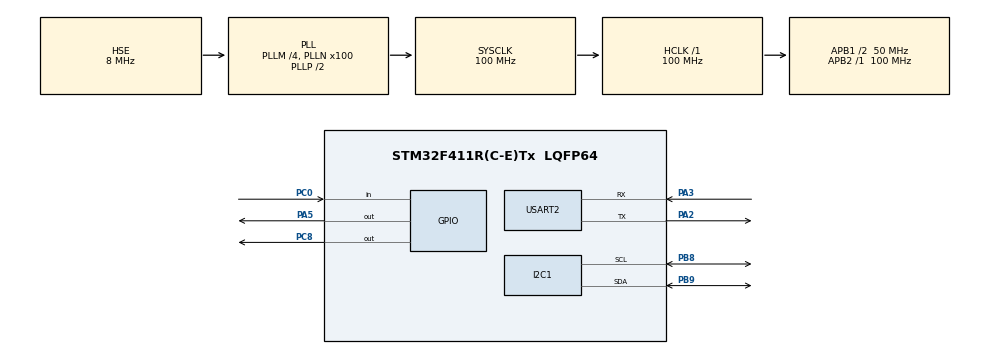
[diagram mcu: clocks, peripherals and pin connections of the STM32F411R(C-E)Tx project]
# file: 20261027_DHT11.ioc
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Mcu.Family=STM32F4
Mcu.Name=STM32F411R(C-E)Tx
Mcu.Package=LQFP64
NVIC.PriorityGroup=NVIC_PRIORITYGROUP_4
PA13.Signal=SYS_JTMS-SWDIO
PA14.Signal=SYS_JTCK-SWCLK
PA2.Mode=Asynchronous
PA2.Signal=USART2_TX
PA3.Mode=Asynchronous
PA3.Signal=USART2_RX
PA5.Signal=GPIO_Output
PB8.Mode=I2C
PB8.Signal=I2C1_SCL
PB9.Mode=I2C
PB9.Signal=I2C1_SDA
PC0.Signal=GPIO_Input
PC8.Signal=GPIO_Output
PH0\ -\ OSC_IN.Mode=HSE-External-Oscillator
PH0\ -\ OSC_IN.Signal=RCC_OSC_IN
PH1\ -\ OSC_OUT.Mode=HSE-External-Oscillator
PH1\ -\ OSC_OUT.Signal=RCC_OSC_OUT
ProjectManager.HeapSize=0x200
ProjectManager.StackSize=0x400
ProjectManager.TargetToolchain=STM32CubeIDE
RCC.48MHZClocksFreq_Value=50000000
RCC.AHBFreq_Value=100000000
RCC.APB1CLKDivider=RCC_HCLK_DIV2
RCC.APB1Freq_Value=50000000
RCC.APB1TimFreq_Value=100000000
RCC.APB2Freq_Value=100000000
RCC.APB2TimFreq_Value=100000000
RCC.CortexFreq_Value=100000000
RCC.HCLKFreq_Value=100000000
RCC.HSE_VALUE=8000000
RCC.HSI_VALUE=16000000
RCC.LSE_VALUE=32768
RCC.PLLM=4
RCC.PLLN=100
RCC.PLLSourceVirtual=RCC_PLLSOURCE_HSE
RCC.SYSCLKFreq_VALUE=100000000
RCC.SYSCLKSource=RCC_SYSCLKSOURCE_PLLCLK
RCC.VCOOutputFreq_Value=200000000
USART2.VirtualMode=VM_ASYNC
board=custom

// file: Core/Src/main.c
/* USER CODE BEGIN Header */
/**
 ******************************************************************************
 * @file           : main.c
 * @brief          : Main program body
 ******************************************************************************
 * @attention
 *
 * Copyright (c) 2026 STMicroelectronics.
 * All rights reserved.
 *
 * This software is licensed under terms that can be found in the LICENSE file
 * in the root directory of this software component.
 * If no LICENSE file comes with this software, it is provided AS-IS.
 *
 ******************************************************************************
 */
/* USER CODE END Header */
#include "main.h"

/* USER CODE BEGIN Includes */
#include <stdio.h>
#include "ap/ap_main.h"
//#include "ap/display/display.h"
/* USER CODE END Includes */

I2C_HandleTypeDef hi2c1;

UART_HandleTypeDef huart2;

void SystemClock_Config(void);
static void MX_GPIO_Init(void);
static void MX_USART2_UART_Init(void);
static void MX_I2C1_Init(void);

/* USER CODE BEGIN 0 */
//int __io_putchar(int ch)
//{
//	HAL_UART_Transmit(&huart2, (uint8_t *)&ch, 1, HAL_MAX_DELAY);
//	return ch;
//}

void power_indicator()
{
	static uint32_t prev_time = 0;
	if (HAL_GetTick() - prev_time < 200) {
		return;
	}
	prev_time = HAL_GetTick();
	HAL_GPIO_TogglePin(GPIOA, GPIO_PIN_5);
}

/* USER CODE END 0 */

int main(void)
{

  /* MCU Configuration--------------------------------------------------------*/

  /* Reset of all peripherals, Initializes the Flash interface and the Systick. */
  HAL_Init();

  /* Configure the system clock */
  SystemClock_Config();

  /* Initialize all configured peripherals */
  MX_GPIO_Init();
  MX_USART2_UART_Init();
  MX_I2C1_Init();
  /* USER CODE BEGIN 2 */
	//printf("hello STM32\n");
  /* USER CODE END 2 */

  /* Infinite loop */
  /* USER CODE BEGIN WHILE */

	//	uint8_t buf[5] = {0};
	//	uint8_t humid_int, humid_dec, temp_int, temp_dec;

	while (1)
	{

    /* USER CODE END WHILE */
		ap_main();
	}
}

void SystemClock_Config(void)
{
  RCC_OscInitTypeDef RCC_OscInitStruct = {0};
  RCC_ClkInitTypeDef RCC_ClkInitStruct = {0};

  /** Configure the main internal regulator output voltage
  */
  __HAL_RCC_PWR_CLK_ENABLE();
  __HAL_PWR_VOLTAGESCALING_CONFIG(PWR_REGULATOR_VOLTAGE_SCALE1);

  /** Initializes the RCC Oscillators according to the specified parameters
  * in the RCC_OscInitTypeDef structure.
  */
  RCC_OscInitStruct.OscillatorType = RCC_OSCILLATORTYPE_HSE;
  RCC_OscInitStruct.HSEState = RCC_HSE_ON;
  RCC_OscInitStruct.PLL.PLLState = RCC_PLL_ON;
  RCC_OscInitStruct.PLL.PLLSource = RCC_PLLSOURCE_HSE;
  RCC_OscInitStruct.PLL.PLLM = 4;
  RCC_OscInitStruct.PLL.PLLN = 100;
  RCC_OscInitStruct.PLL.PLLP = RCC_PLLP_DIV2;
  RCC_OscInitStruct.PLL.PLLQ = 4;
  if (HAL_RCC_OscConfig(&RCC_OscInitStruct) != HAL_OK)
  {
    Error_Handler();
  }

  /** Initializes the CPU, AHB and APB buses clocks
  */
  RCC_ClkInitStruct.ClockType = RCC_CLOCKTYPE_HCLK|RCC_CLOCKTYPE_SYSCLK
                              |RCC_CLOCKTYPE_PCLK1|RCC_CLOCKTYPE_PCLK2;
  RCC_ClkInitStruct.SYSCLKSource = RCC_SYSCLKSOURCE_PLLCLK;
  RCC_ClkInitStruct.AHBCLKDivider = RCC_SYSCLK_DIV1;
  RCC_ClkInitStruct.APB1CLKDivider = RCC_HCLK_DIV2;
  RCC_ClkInitStruct.APB2CLKDivider = RCC_HCLK_DIV1;

  if (HAL_RCC_ClockConfig(&RCC_ClkInitStruct, FLASH_LATENCY_3) != HAL_OK)
  {
    Error_Handler();
  }
}

static void MX_I2C1_Init(void)
{

  hi2c1.Instance = I2C1;
  hi2c1.Init.ClockSpeed = 100000;
  hi2c1.Init.DutyCycle = I2C_DUTYCYCLE_2;
  hi2c1.Init.OwnAddress1 = 0;
  hi2c1.Init.AddressingMode = I2C_ADDRESSINGMODE_7BIT;
  hi2c1.Init.DualAddressMode = I2C_DUALADDRESS_DISABLE;
  hi2c1.Init.OwnAddress2 = 0;
  hi2c1.Init.GeneralCallMode = I2C_GENERALCALL_DISABLE;
  hi2c1.Init.NoStretchMode = I2C_NOSTRETCH_DISABLE;
  if (HAL_I2C_Init(&hi2c1) != HAL_OK)
  {
    Error_Handler();
  }

}

static void MX_USART2_UART_Init(void)
{

  huart2.Instance = USART2;
  huart2.Init.BaudRate = 115200;
  huart2.Init.WordLength = UART_WORDLENGTH_8B;
  huart2.Init.StopBits = UART_STOPBITS_1;
  huart2.Init.Parity = UART_PARITY_NONE;
  huart2.Init.Mode = UART_MODE_TX_RX;
  huart2.Init.HwFlowCtl = UART_HWCONTROL_NONE;
  huart2.Init.OverSampling = UART_OVERSAMPLING_16;
  if (HAL_UART_Init(&huart2) != HAL_OK)
  {
    Error_Handler();
  }

}

static void MX_GPIO_Init(void)
{
  GPIO_InitTypeDef GPIO_InitStruct = {0};

  /* GPIO Ports Clock Enable */
  __HAL_RCC_GPIOH_CLK_ENABLE();
  __HAL_RCC_GPIOC_CLK_ENABLE();
  __HAL_RCC_GPIOA_CLK_ENABLE();
  __HAL_RCC_GPIOB_CLK_ENABLE();

  /*Configure GPIO pin Output Level */
  HAL_GPIO_WritePin(GPIOA, GPIO_PIN_5, GPIO_PIN_RESET);

  /*Configure GPIO pin Output Level */
  HAL_GPIO_WritePin(GPIOC, GPIO_PIN_8, GPIO_PIN_RESET);

  /*Configure GPIO pin : PC0 */
  GPIO_InitStruct.Pin = GPIO_PIN_0;
  GPIO_InitStruct.Mode = GPIO_MODE_INPUT;
  GPIO_InitStruct.Pull = GPIO_NOPULL;
  HAL_GPIO_Init(GPIOC, &GPIO_InitStruct);

  /*Configure GPIO pin : PA5 */
  GPIO_InitStruct.Pin = GPIO_PIN_5;
  GPIO_InitStruct.Mode = GPIO_MODE_OUTPUT_PP;
  GPIO_InitStruct.Pull = GPIO_NOPULL;
  GPIO_InitStruct.Speed = GPIO_SPEED_FREQ_LOW;
  HAL_GPIO_Init(GPIOA, &GPIO_InitStruct);

  /*Configure GPIO pin : PC8 */
  GPIO_InitStruct.Pin = GPIO_PIN_8;
  GPIO_InitStruct.Mode = GPIO_MODE_OUTPUT_PP;
  GPIO_InitStruct.Pull = GPIO_NOPULL;
  GPIO_InitStruct.Speed = GPIO_SPEED_FREQ_LOW;
  HAL_GPIO_Init(GPIOC, &GPIO_InitStruct);

}

void Error_Handler(void)
{
	__disable_irq();
	while (1)
	{
	}
}
